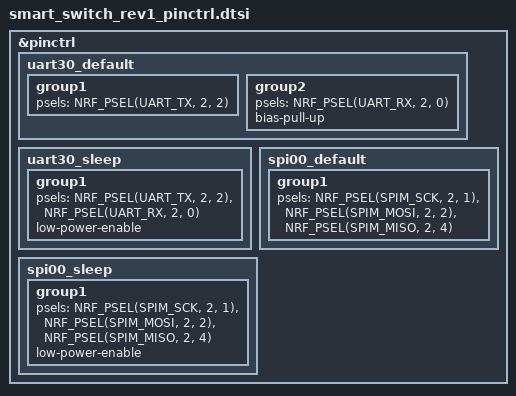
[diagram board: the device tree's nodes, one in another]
/*
 * Copyright (c) 2024 Nordic Semiconductor
 * SPDX-License-Identifier: Apache-2.0
 */

&pinctrl {
	/omit-if-no-ref/ uart30_default: uart30_default {
		group1 {
			psels = <NRF_PSEL(UART_TX, 2, 2)>;
		};

		group2 {
			psels = <NRF_PSEL(UART_RX, 2, 0)>;
			bias-pull-up;
		};
	};

	/omit-if-no-ref/ uart30_sleep: uart30_sleep {
		group1 {
			psels = <NRF_PSEL(UART_TX, 2, 2)>,
				<NRF_PSEL(UART_RX, 2, 0)>;
			low-power-enable;
		};
	};

	/omit-if-no-ref/ spi00_default: spi00_default {
		group1 {
			psels = <NRF_PSEL(SPIM_SCK, 2, 1)>,
				<NRF_PSEL(SPIM_MOSI, 2, 2)>,
				<NRF_PSEL(SPIM_MISO, 2, 4)>;
		};
	};

	/omit-if-no-ref/ spi00_sleep: spi00_sleep {
		group1 {
			psels = <NRF_PSEL(SPIM_SCK, 2, 1)>,
				<NRF_PSEL(SPIM_MOSI, 2, 2)>,
				<NRF_PSEL(SPIM_MISO, 2, 4)>;
				low-power-enable;
		};
	};
};
